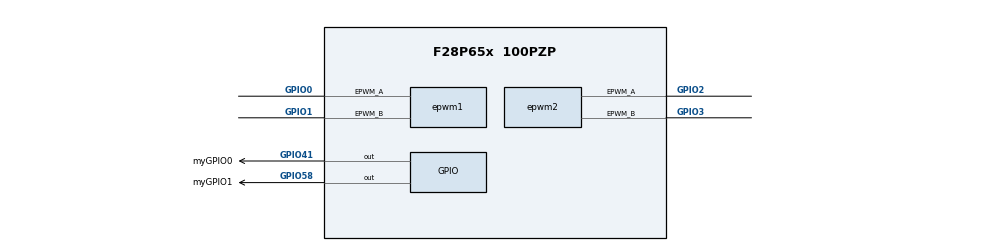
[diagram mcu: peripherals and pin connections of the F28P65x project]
/**
 * @cliArgs --device "F28P65x" --part "F28P65x_100PZP" --package "100PZP" --context "CPU1" --product "C2000WARE@5.04.00.00"
 * @versions {"tool":"1.23.0+4000"}
 */

/**
 * Import the modules used in this configuration.
 */
const adc     = scripting.addModule("/driverlib/adc.js", {}, false);
const adc1    = adc.addInstance();
const adc2    = adc.addInstance();
const analog  = scripting.addModule("/driverlib/analog.js", {}, false);
const analog1 = analog.addInstance();
const asysctl = scripting.addModule("/driverlib/asysctl.js");
const epwm    = scripting.addModule("/driverlib/epwm.js", {}, false);
const epwm1   = epwm.addInstance();
const epwm2   = epwm.addInstance();
const gpio    = scripting.addModule("/driverlib/gpio.js", {}, false);
const gpio1   = gpio.addInstance();
const gpio2   = gpio.addInstance();

/**
 * Write custom configuration values to the imported modules.
 */
adc1.$name                          = "myADC0";
adc1.adcClockPrescaler              = "ADC_CLK_DIV_4_0";
adc1.enabledSOCs                    = ["ADC_SOC_NUMBER0"];
adc1.adcBase                        = "ADCB_BASE";
adc1.soc0Channel                    = "ADC_CH_ADCIN2";
adc1.soc0IndependentNameMode        = true;
adc1.soc0Trigger                    = "ADC_TRIGGER_EPWM1_SOCA";
adc1.enabledInts                    = ["ADC_INT_NUMBER1"];
adc1.enableInterrupt1               = true;
adc1.enableInterrupt1ContinuousMode = true;
adc1.interruptPulseMode             = "ADC_PULSE_END_OF_CONV";
adc1.registerInterrupts             = ["1"];
adc1.adcResolutionMode              = "ADC_RESOLUTION_16BIT";
adc1.soc0SampleWindow               = 100;
adc1.adcInt1.enableInterrupt        = true;

adc2.$name                   = "ADC_Current";
adc2.adcClockPrescaler       = "ADC_CLK_DIV_4_0";
adc2.adcResolutionMode       = "ADC_RESOLUTION_16BIT";
adc2.soc1IndependentNameMode = true;
adc2.adcBase                 = "ADCC_BASE";
adc2.soc1Channel             = "ADC_CH_ADCIN3";
adc2.useInterrupts           = false;
adc2.soc0Channel             = "ADC_CH_ADCIN3";
adc2.soc0Name                = "SOC1";
adc2.soc0IndependentNameMode = true;
adc2.soc0SampleWindow        = 100;
adc2.enabledSOCs             = ["ADC_SOC_NUMBER1"];
adc2.soc1Trigger             = "ADC_TRIGGER_EPWM1_SOCA";
adc2.soc1SampleWindow        = 64;

analog1.$name            = "myANALOGPinMux0";
adc1.analog              = analog1;
analog1.useCase          = "CUSTOM";
adc2.analog              = analog1;
analog1.useInterfacePins = ["B2","C3, GPIO206"];

asysctl.analogReferenceVoltage = "1P65";
asysctl.analogReference        = "INTERNAL";

epwm1.epwmTimebase_hsClockDiv                                    = "EPWM_HSCLOCK_DIVIDER_1";
epwm1.epwmTimebase_counterMode                                   = "EPWM_COUNTER_MODE_UP_DOWN";
epwm1.epwmTimebase_syncInPulseSource                             = "EPWM_SYNC_IN_PULSE_SRC_DISABLE";
epwm1.epwmActionQualifier_EPWM_AQ_OUTPUT_A_ON_TIMEBASE_UP_CMPA   = "EPWM_AQ_OUTPUT_HIGH";
epwm1.epwmActionQualifier_EPWM_AQ_OUTPUT_A_ON_TIMEBASE_DOWN_CMPA = "EPWM_AQ_OUTPUT_LOW";
epwm1.$name                                                      = "myEPWM1";
epwm1.epwmDeadband_delayRED                                      = 80;
epwm1.epwmDeadband_delayFED                                      = 80;
epwm1.epwmDeadband_outputSwapOutA                                = true;
epwm1.epwmDeadband_polarityRED                                   = "EPWM_DB_POLARITY_ACTIVE_LOW";
epwm1.epwmDeadband_enableRED                                     = true;
epwm1.epwmDeadband_enableFED                                     = true;
epwm1.epwmDeadband_outputSwapOutB                                = true;
epwm1.epwmEventTrigger_EPWM_SOC_A_triggerEnable                  = true;
epwm1.epwmEventTrigger_EPWM_SOC_A_triggerEventPrescalar          = "1";
epwm1.epwmEventTrigger_EPWM_SOC_A_triggerSource                  = "EPWM_SOC_TBCTR_U_CMPA";
epwm1.epwmEventTrigger_EPWM_SOC_A_triggerEventCountInitEnable    = true;
epwm1.epwmTimebase_period                                        = 1666;
epwm1.epwm.$assign                                               = "EPWM1";
epwm1.epwm.epwm_aPin.$assign                                     = "GPIO0";
epwm1.epwm.epwm_bPin.$assign                                     = "GPIO1";

epwm2.$name                                                      = "myEPWM2";
epwm2.epwmTimebase_hsClockDiv                                    = "EPWM_HSCLOCK_DIVIDER_1";
epwm2.epwmTimebase_counterMode                                   = "EPWM_COUNTER_MODE_UP_DOWN";
epwm2.epwmTimebase_syncInPulseSource                             = "EPWM_SYNC_IN_PULSE_SRC_DISABLE";
epwm2.epwmActionQualifier_EPWM_AQ_OUTPUT_A_ON_TIMEBASE_UP_CMPA   = "EPWM_AQ_OUTPUT_HIGH";
epwm2.epwmActionQualifier_EPWM_AQ_OUTPUT_A_ON_TIMEBASE_DOWN_CMPA = "EPWM_AQ_OUTPUT_LOW";
epwm2.epwmDeadband_outputSwapOutA                                = true;
epwm2.epwmDeadband_delayFED                                      = 80;
epwm2.epwmDeadband_delayRED                                      = 80;
epwm2.epwmDeadband_polarityRED                                   = "EPWM_DB_POLARITY_ACTIVE_LOW";
epwm2.epwmDeadband_enableRED                                     = true;
epwm2.epwmDeadband_enableFED                                     = true;
epwm2.epwmDeadband_outputSwapOutB                                = true;
epwm2.epwmTimebase_period                                        = 1666;
epwm2.epwm.$assign                                               = "EPWM2";
epwm2.epwm.epwm_aPin.$assign                                     = "GPIO2";
epwm2.epwm.epwm_bPin.$assign                                     = "GPIO3";

gpio1.$name           = "myGPIO0";
gpio1.direction       = "GPIO_DIR_MODE_OUT";
gpio1.gpioPin.$assign = "GPIO41";

gpio2.$name           = "myGPIO1";
gpio2.direction       = "GPIO_DIR_MODE_OUT";
gpio2.gpioPin.$assign = "GPIO58";

/**
 * Pinmux solution for unlocked pins/peripherals. This ensures that minor changes to the automatic solver in a future
 * version of the tool will not impact the pinmux you originally saw.  These lines can be completely deleted in order to
 * re-solve from scratch.
 */
analog1.analog.$suggestSolution                   = "ANALOG";
analog1.analog.b2Pin.$suggestSolution             = "B2";
analog1.analog["c3, gpio206Pin"].$suggestSolution = "C3, GPIO206";
